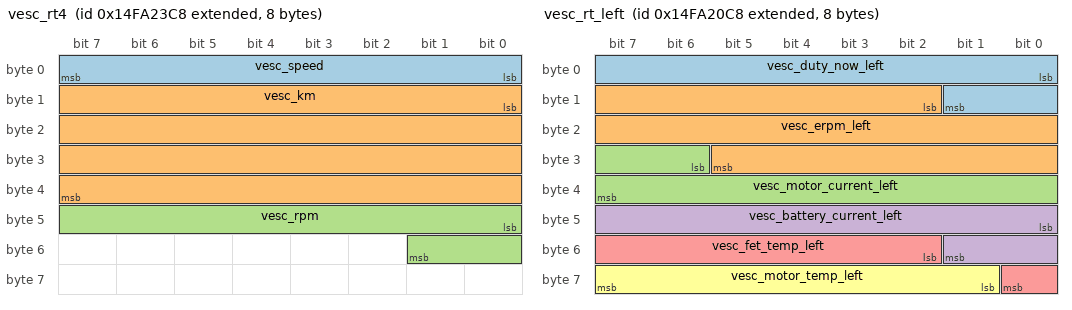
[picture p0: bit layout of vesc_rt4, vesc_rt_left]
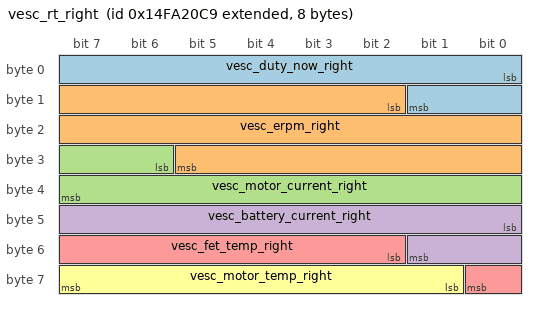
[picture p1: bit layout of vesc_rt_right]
VERSION ""

NS_ :

BS_:

BU_:

BO_ 2499421128  vesc_rt4  			: 8 Vector__XXX
 SG_ vesc_speed  :	    0|8 @1+(1,0)       	     		        [0|100]        "" Vector__XXX
 SG_ vesc_km     :	    8|32 @1+(0.1,0)       	     	        [0|4294967295] "" Vector__XXX
 SG_ vesc_rpm    :	   40|10 @1+(1,0)       	     		    [0|100000]     "" Vector__XXX

BO_ 2350041248 SLAVE3_UPDATE_MASTER_FEEDBACK_PGN    : 5 Vector__XXX
 SG_ LOAD_SPEC      :      0|32 @1+ (0.001,-100000)         [-100000|100000] "" Vector__XXX
 SG_ ACTION_SPEC    :     32|4  @1+ (1,0)                     [0|8] "" Vector__XXX

BO_ 2350041504 SLAVE2_UPDATE_MASTER_FEEDBACK_PGN    : 5 Vector__XXX
 SG_ LOAD_SPEC      :      0|32 @1+ (0.001,-100000)         [-100000|100000] "" Vector__XXX
 SG_ ACTION_SPEC    :     32|4  @1+ (1,0)                     [0|8] "" Vector__XXX

BO_ 2350055328 SLAVE1_UPDATE_MASTER_FEEDBACK_PGN    : 5 Vector__XXX
 SG_ LOAD_SPEC      :      0|32 @1+ (0.001,-100000)         [-100000|100000] "" Vector__XXX
 SG_ ACTION_SPEC    :     32|4  @1+ (1,0)                     [0|8] "" Vector__XXX

BO_ 2499420360  vesc_rt_left   			:8 Vector__XXX
 SG_ vesc_duty_now_left	:	0|10 @1+(0.002,-1)       	     		[-1|1] "" Vector__XXX
 SG_ vesc_erpm_left	:	10|20 @1+(1,-50000)       	    		    [-50000|50000] "" Vector__XXX
 SG_ vesc_motor_current_left:	30|10 @1+(0.2,-100)       		    [-100|100] "" Vector__XXX
 SG_ vesc_battery_current_left:	40|10 @1+(0.2,-100)       		[-100|100] "" Vector__XXX
 SG_ vesc_fet_temp_left	:	50|7 @1+(1,-20)       	     		[-20|100] "" Vector__XXX
 SG_ vesc_motor_temp_left:	57|7 @1+(1,-20)       	     		[-20|100] "" Vector__XXX

BO_ 2499420361  vesc_rt_right   			:8 Vector__XXX
 SG_ vesc_duty_now_right	:	0|10 @1+(0.002,-1)       	     		[-1|1] "" Vector__XXX
 SG_ vesc_erpm_right	:	10|20 @1+(1,-50000)       	    		    [-50000|50000] "" Vector__XXX
 SG_ vesc_motor_current_right:	30|10 @1+(0.2,-100)       		    [-100|100] "" Vector__XXX
 SG_ vesc_battery_current_right:	40|10 @1+(0.2,-100)       		[-100|100] "" Vector__XXX
 SG_ vesc_fet_temp_right	:	50|7 @1+(1,-20)       	     		[-20|100] "" Vector__XXX
 SG_ vesc_motor_temp_right:	57|7 @1+(1,-20)       	     		[-20|100] "" Vector__XXX

BA_DEF_ BO_  "VFrameFormat" ENUM  "StandardCAN","ExtendedCAN","reserved","J1939PG";
BA_DEF_  "DatabaseVersion" STRING ;
BA_DEF_  "BusType" STRING ;
BA_DEF_  "ProtocolType" STRING ;
BA_DEF_  "DatabaseCompiler" STRING ;

BA_DEF_DEF_  "VFrameFormat" "J1939PG";
BA_DEF_DEF_  "DatabaseVersion" "";
BA_DEF_DEF_  "BusType" "";
BA_DEF_DEF_  "ProtocolType" "";
BA_DEF_DEF_  "DatabaseCompiler" "";

BA_ "ProtocolType" "J1939";
BA_ "BusType" "CAN";
BA_ "DatabaseCompiler" "CSS ELECTRONICS (WWW.CSSELECTRONICS.COM)";
BA_ "DatabaseVersion" "1.0.0";
